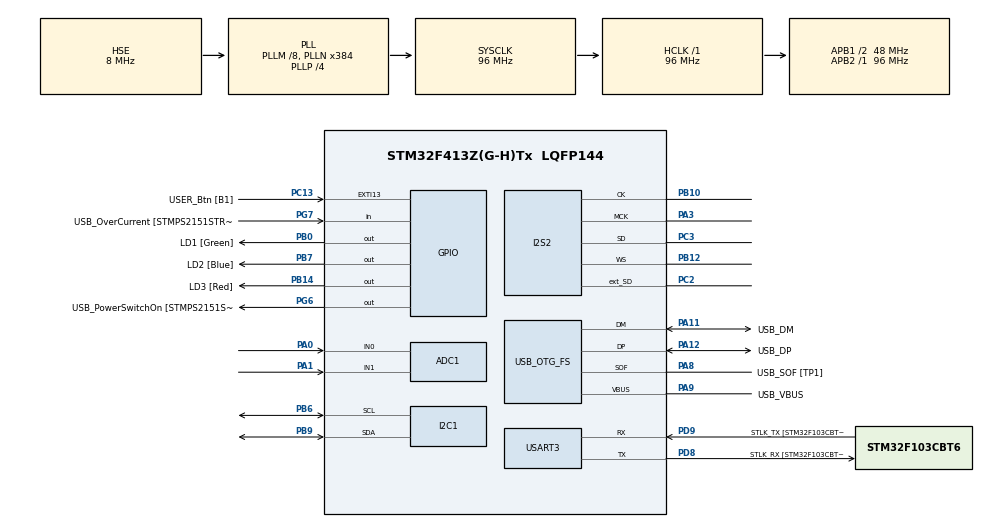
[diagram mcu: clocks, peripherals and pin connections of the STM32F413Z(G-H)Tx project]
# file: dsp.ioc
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ADC1.Channel-0\#ChannelRegularConversion=ADC_CHANNEL_0
ADC1.NbrOfConversionFlag=1
ADC1.Rank-0\#ChannelRegularConversion=1
ADC1.SamplingTime-0\#ChannelRegularConversion=ADC_SAMPLETIME_3CYCLES
ADC1.master=1
Dma.I2S2_EXT_RX.0.Direction=DMA_PERIPH_TO_MEMORY
Dma.I2S2_EXT_RX.0.FIFOMode=DMA_FIFOMODE_DISABLE
Dma.I2S2_EXT_RX.0.Instance=DMA1_Stream3
Dma.I2S2_EXT_RX.0.MemDataAlignment=DMA_MDATAALIGN_HALFWORD
Dma.I2S2_EXT_RX.0.MemInc=DMA_MINC_ENABLE
Dma.I2S2_EXT_RX.0.Mode=DMA_CIRCULAR
Dma.I2S2_EXT_RX.0.PeriphDataAlignment=DMA_PDATAALIGN_HALFWORD
Dma.I2S2_EXT_RX.0.PeriphInc=DMA_PINC_DISABLE
Dma.I2S2_EXT_RX.0.Priority=DMA_PRIORITY_LOW
Dma.Request0=I2S2_EXT_RX
Dma.Request1=SPI2_TX
Dma.SPI2_TX.1.Direction=DMA_MEMORY_TO_PERIPH
Dma.SPI2_TX.1.FIFOMode=DMA_FIFOMODE_DISABLE
Dma.SPI2_TX.1.Instance=DMA1_Stream4
Dma.SPI2_TX.1.MemDataAlignment=DMA_MDATAALIGN_HALFWORD
Dma.SPI2_TX.1.MemInc=DMA_MINC_ENABLE
Dma.SPI2_TX.1.Mode=DMA_CIRCULAR
Dma.SPI2_TX.1.PeriphDataAlignment=DMA_PDATAALIGN_HALFWORD
Dma.SPI2_TX.1.PeriphInc=DMA_PINC_DISABLE
Dma.SPI2_TX.1.Priority=DMA_PRIORITY_LOW
I2S2.AudioFreq=I2S_AUDIOFREQ_44K
I2S2.ErrorAudioFreq=-1.35 %
I2S2.FullDuplexMode=I2S_FULLDUPLEXMODE_ENABLE
I2S2.Instance=SPI$Index
I2S2.RealAudioFreq=43.402 KHz
I2S2.Standard=I2S_STANDARD_MSB
I2S2.VirtualMode=I2S_MODE_MASTER
Mcu.Family=STM32F4
Mcu.Name=STM32F413Z(G-H)Tx
Mcu.Package=LQFP144
NVIC.DMA1_Stream3_IRQn=true\:0\:0\:false\:false\:true\:false\:true
NVIC.DMA1_Stream4_IRQn=true\:0\:0\:false\:false\:true\:false\:true
NVIC.PriorityGroup=NVIC_PRIORITYGROUP_4
PA0.Signal=ADCx_IN0
PA1.Signal=ADCx_IN1
PA10.GPIO_Label=USB_ID
PA10.Signal=USB_OTG_FS_ID
PA11.GPIO_Label=USB_DM
PA11.Mode=Device_Only
PA11.Signal=USB_OTG_FS_DM
PA12.GPIO_Label=USB_DP
PA12.Mode=Device_Only
PA12.Signal=USB_OTG_FS_DP
PA13.GPIO_Label=TMS
PA13.Mode=Serial_Wire
PA13.Signal=SYS_JTMS-SWDIO
PA14.GPIO_Label=TCK
PA14.Mode=Serial_Wire
PA14.Signal=SYS_JTCK-SWCLK
PA3.Mode=Master_Clock_Activated
PA3.Signal=I2S2_MCK
PA8.GPIO_Label=USB_SOF [TP1]
PA8.Mode=Activate_SOF_FS
PA8.Signal=USB_OTG_FS_SOF
PA9.GPIO_Label=USB_VBUS
PA9.Mode=Activate_VBUS
PA9.Signal=USB_OTG_FS_VBUS
PB0.GPIO_Label=LD1 [Green]
PB0.Signal=GPIO_Output
PB10.Mode=Full_Duplex_Master
PB10.Signal=I2S2_CK
PB12.Mode=Full_Duplex_Master
PB12.Signal=I2S2_WS
PB14.GPIO_Label=LD3 [Red]
PB14.Signal=GPIO_Output
PB3.GPIO_Label=SWO
PB3.Signal=SYS_JTDO-SWO
PB6.Mode=I2C
PB6.Signal=I2C1_SCL
PB7.GPIO_Label=LD2 [Blue]
PB7.Signal=GPIO_Output
PB9.Mode=I2C
PB9.Signal=I2C1_SDA
PC13.GPIO_Label=USER_Btn [B1]
PC13.Signal=GPXTI13
PC14-OSC32_IN.Mode=LSE-External-Oscillator
PC14-OSC32_IN.Signal=RCC_OSC32_IN
PC15-OSC32_OUT.Mode=LSE-External-Oscillator
PC15-OSC32_OUT.Signal=RCC_OSC32_OUT
PC2.Mode=Full_Duplex_Master
PC2.Signal=I2S2_ext_SD
PC3.Mode=Full_Duplex_Master
PC3.Signal=I2S2_SD
PD8.GPIO_Label=STLK_RX [STM32F103CBT6_PA3]
PD8.Mode=Asynchronous
PD8.Signal=USART3_TX
PD9.GPIO_Label=STLK_TX [STM32F103CBT6_PA2]
PD9.Mode=Asynchronous
PD9.Signal=USART3_RX
PG6.GPIO_Label=USB_PowerSwitchOn [STMPS2151STR_EN]
PG6.Signal=GPIO_Output
PG7.GPIO_Label=USB_OverCurrent [STMPS2151STR_FAULT]
PG7.Signal=GPIO_Input
PH0\ -\ OSC_IN.GPIO_Label=MCO
PH0\ -\ OSC_IN.Mode=HSE-External-Clock-Source
PH0\ -\ OSC_IN.Signal=RCC_OSC_IN
PH1\ -\ OSC_OUT.Mode=HSE-External-Clock-Source
PH1\ -\ OSC_OUT.Signal=RCC_OSC_OUT
ProjectManager.HeapSize=0x200
ProjectManager.StackSize=0x400
ProjectManager.TargetToolchain=Makefile
RCC.48MHZClocksFreq_Value=24000000
RCC.AHBFreq_Value=96000000
RCC.APB1CLKDivider=RCC_HCLK_DIV2
RCC.APB1Freq_Value=48000000
RCC.APB1TimFreq_Value=96000000
RCC.APB2Freq_Value=96000000
RCC.APB2TimFreq_Value=96000000
RCC.CortexFreq_Value=96000000
RCC.HCLKFreq_Value=96000000
RCC.HSE_VALUE=8000000
RCC.HSI_VALUE=16000000
RCC.PLLI2SM=4
RCC.PLLI2SN=200
RCC.PLLM=8
RCC.PLLMUL=RCC_PLL_MUL9
RCC.PLLN=384
RCC.PLLP=RCC_PLLP_DIV4
RCC.PLLQ=8
RCC.PRESCALERUSB=RCC_USBCLKSOURCE_PLL_DIV1_5
RCC.SYSCLKFreq_VALUE=96000000
RCC.SYSCLKSource=RCC_SYSCLKSOURCE_PLLCLK
RCC.SYSCLKSourceVirtual=RCC_SYSCLKSOURCE_PLLCLK
RCC.USBFreq_Value=48000000
RCC.VCOOutputFreq_Value=384000000
SH.ADCx_IN0.0=ADC1_IN0,IN0
SH.ADCx_IN1.0=ADC1_IN1,IN1
USART3.VirtualMode=VM_ASYNC
USB_OTG_FS.VirtualMode=Device_Only
board=NUCLEO-F413ZH

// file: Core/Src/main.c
/* USER CODE BEGIN Header */
/**
  ******************************************************************************
  * @file           : main.c
  * @brief          : Main program body
  ******************************************************************************
  * @attention
  *
  * <h2><center>&copy; Copyright (c) 2021 STMicroelectronics.
  * All rights reserved.</center></h2>
  *
  * This software component is licensed by ST under BSD 3-Clause license,
  * the "License"; You may not use this file except in compliance with the
  * License. You may obtain a copy of the License at:
  *                        opensource.org/licenses/BSD-3-Clause
  *
  ******************************************************************************
  */
/* USER CODE END Header */
#include "main.h"

/* USER CODE BEGIN Includes */
#include "application.hpp"

////////////connection to codec//////////////
// pA3 ---> MCLK
// pB10 --> SCLK
// pB12 --> LRCLK
// pC2 ---> MISO (ADC)
// pC3 ---> MOSI (DAC)
//
// pB6 ---> SCL
// pB9 ---> SDA
/////////////////////////////////////////////

/* USER CODE END Includes */

ADC_HandleTypeDef hadc1;

I2C_HandleTypeDef hi2c1;

I2S_HandleTypeDef hi2s2;
DMA_HandleTypeDef hdma_i2s2_ext_rx;
DMA_HandleTypeDef hdma_spi2_tx;

UART_HandleTypeDef huart3;

PCD_HandleTypeDef hpcd_USB_OTG_FS;

void SystemClock_Config(void);
static void MX_GPIO_Init(void);
static void MX_DMA_Init(void);
static void MX_I2S2_Init(void);
static void MX_USART3_UART_Init(void);
static void MX_USB_OTG_FS_PCD_Init(void);
static void MX_ADC1_Init(void);
static void MX_I2C1_Init(void);

/* USER CODE BEGIN 0 */

int wait = 0;

/* USER CODE END 0 */

int main(void)
{

  /* MCU Configuration--------------------------------------------------------*/

  /* Reset of all peripherals, Initializes the Flash interface and the Systick. */
  HAL_Init();

  /* Configure the system clock */
  SystemClock_Config();

  /* Initialize all configured peripherals */
  MX_GPIO_Init();
  MX_DMA_Init();
  MX_I2S2_Init();
  MX_USART3_UART_Init();
  MX_USB_OTG_FS_PCD_Init();
  MX_ADC1_Init();
  MX_I2C1_Init();
  /* USER CODE BEGIN 2 */

  for(int i = 0; i < 1000000; i++);
  setup();
  for(int i = 0; i < 1000000; i++);
  HAL_I2SEx_TransmitReceive_DMA(&hi2s2, txBuf, rxBuf, 4);

  /* USER CODE END 2 */

  /* Infinite loop */
  while (1)
  {

  }
}

void HAL_I2SEx_TxRxHalfCpltCallback(I2S_HandleTypeDef *hi2s){
  do_process(&rxBuf[0],&rxBuf[1],&txBuf[0],&txBuf[1]);    //in,in,out,out
  //txBuf[0] = rxBuf[0];
  //txBuf[1] = rxBuf[1];
}

//this is not firing with default code!!!  see below.
//note:
//need to change I2SEx_TxRxDMACplt in stm32f4xx_hal_i2s_ex.c, so that it ends like:
//   }
//   HAL_I2SEx_TxRxCpltCallback(hi2s);
// }
//instead of:
//     }
//   }
// }
// https://community.st.com/s/question/0D50X0000AAJFwVSQX/bug-hali2sextxrxcpltcallback-never-fire-in-dma-circular-mode
void HAL_I2SEx_TxRxCpltCallback(I2S_HandleTypeDef *hi2s){
  //do_process(&rxBuf[2],&rxBuf[3],&txBuf[2],&txBuf[3]);
  txBuf[2] = 0;
  txBuf[3] = 0;
}

void SystemClock_Config(void)
{
  RCC_OscInitTypeDef RCC_OscInitStruct = {0};
  RCC_ClkInitTypeDef RCC_ClkInitStruct = {0};
  RCC_PeriphCLKInitTypeDef PeriphClkInitStruct = {0};

  /** Configure the main internal regulator output voltage
  */
  __HAL_RCC_PWR_CLK_ENABLE();
  __HAL_PWR_VOLTAGESCALING_CONFIG(PWR_REGULATOR_VOLTAGE_SCALE1);
  /** Initializes the RCC Oscillators according to the specified parameters
  * in the RCC_OscInitTypeDef structure.
  */
  RCC_OscInitStruct.OscillatorType = RCC_OSCILLATORTYPE_HSE;
  RCC_OscInitStruct.HSEState = RCC_HSE_BYPASS;
  RCC_OscInitStruct.PLL.PLLState = RCC_PLL_ON;
  RCC_OscInitStruct.PLL.PLLSource = RCC_PLLSOURCE_HSE;
  RCC_OscInitStruct.PLL.PLLM = 8;
  RCC_OscInitStruct.PLL.PLLN = 384;
  RCC_OscInitStruct.PLL.PLLP = RCC_PLLP_DIV4;
  RCC_OscInitStruct.PLL.PLLQ = 8;
  RCC_OscInitStruct.PLL.PLLR = 2;
  if (HAL_RCC_OscConfig(&RCC_OscInitStruct) != HAL_OK)
  {
    Error_Handler();
  }
  /** Initializes the CPU, AHB and APB buses clocks
  */
  RCC_ClkInitStruct.ClockType = RCC_CLOCKTYPE_HCLK|RCC_CLOCKTYPE_SYSCLK
                              |RCC_CLOCKTYPE_PCLK1|RCC_CLOCKTYPE_PCLK2;
  RCC_ClkInitStruct.SYSCLKSource = RCC_SYSCLKSOURCE_PLLCLK;
  RCC_ClkInitStruct.AHBCLKDivider = RCC_SYSCLK_DIV1;
  RCC_ClkInitStruct.APB1CLKDivider = RCC_HCLK_DIV2;
  RCC_ClkInitStruct.APB2CLKDivider = RCC_HCLK_DIV1;

  if (HAL_RCC_ClockConfig(&RCC_ClkInitStruct, FLASH_LATENCY_3) != HAL_OK)
  {
    Error_Handler();
  }
  PeriphClkInitStruct.PeriphClockSelection = RCC_PERIPHCLK_I2S_APB1|RCC_PERIPHCLK_CLK48;
  PeriphClkInitStruct.PLLI2S.PLLI2SN = 260;     //200
  PeriphClkInitStruct.PLLI2S.PLLI2SM = 4;
  PeriphClkInitStruct.PLLI2S.PLLI2SR = 2;
  PeriphClkInitStruct.PLLI2S.PLLI2SQ = 2;
  PeriphClkInitStruct.Clk48ClockSelection = RCC_CLK48CLKSOURCE_PLLQ;
  PeriphClkInitStruct.PLLI2SSelection = RCC_PLLI2SCLKSOURCE_PLLSRC;
  PeriphClkInitStruct.I2sApb1ClockSelection = RCC_I2SAPB1CLKSOURCE_PLLI2S;
  if (HAL_RCCEx_PeriphCLKConfig(&PeriphClkInitStruct) != HAL_OK)
  {
    Error_Handler();
  }
}

static void MX_ADC1_Init(void)
{

  ADC_ChannelConfTypeDef sConfig = {0};

  /** Configure the global features of the ADC (Clock, Resolution, Data Alignment and number of conversion)
  */
  hadc1.Instance = ADC1;
  hadc1.Init.ClockPrescaler = ADC_CLOCK_SYNC_PCLK_DIV4;
  hadc1.Init.Resolution = ADC_RESOLUTION_12B;
  hadc1.Init.ScanConvMode = DISABLE;
  hadc1.Init.ContinuousConvMode = DISABLE;
  hadc1.Init.DiscontinuousConvMode = DISABLE;
  hadc1.Init.ExternalTrigConvEdge = ADC_EXTERNALTRIGCONVEDGE_NONE;
  hadc1.Init.ExternalTrigConv = ADC_SOFTWARE_START;
  hadc1.Init.DataAlign = ADC_DATAALIGN_RIGHT;
  hadc1.Init.NbrOfConversion = 1;
  hadc1.Init.DMAContinuousRequests = DISABLE;
  hadc1.Init.EOCSelection = ADC_EOC_SINGLE_CONV;
  if (HAL_ADC_Init(&hadc1) != HAL_OK)
  {
    Error_Handler();
  }
  /** Configure for the selected ADC regular channel its corresponding rank in the sequencer and its sample time.
  */
  sConfig.Channel = ADC_CHANNEL_0;
  sConfig.Rank = 1;
  sConfig.SamplingTime = ADC_SAMPLETIME_3CYCLES;
  if (HAL_ADC_ConfigChannel(&hadc1, &sConfig) != HAL_OK)
  {
    Error_Handler();
  }

}

static void MX_I2C1_Init(void)
{

  hi2c1.Instance = I2C1;
  hi2c1.Init.ClockSpeed = 100000;
  hi2c1.Init.DutyCycle = I2C_DUTYCYCLE_2;
  hi2c1.Init.OwnAddress1 = 0;
  hi2c1.Init.AddressingMode = I2C_ADDRESSINGMODE_7BIT;
  hi2c1.Init.DualAddressMode = I2C_DUALADDRESS_DISABLE;
  hi2c1.Init.OwnAddress2 = 0;
  hi2c1.Init.GeneralCallMode = I2C_GENERALCALL_DISABLE;
  hi2c1.Init.NoStretchMode = I2C_NOSTRETCH_DISABLE;
  if (HAL_I2C_Init(&hi2c1) != HAL_OK)
  {
    Error_Handler();
  }

}

static void MX_I2S2_Init(void)
{

  hi2s2.Instance = SPI2;
  hi2s2.Init.Mode = I2S_MODE_MASTER_TX;
  hi2s2.Init.Standard = I2S_STANDARD_MSB;
  hi2s2.Init.DataFormat = I2S_DATAFORMAT_16B;
  hi2s2.Init.MCLKOutput = I2S_MCLKOUTPUT_ENABLE;
  hi2s2.Init.AudioFreq = I2S_AUDIOFREQ_48K;               //there's some oscillation with the setting of 44k here...
  hi2s2.Init.CPOL = I2S_CPOL_LOW;
  hi2s2.Init.ClockSource = I2S_CLOCK_PLL;
  hi2s2.Init.FullDuplexMode = I2S_FULLDUPLEXMODE_ENABLE;
  if (HAL_I2S_Init(&hi2s2) != HAL_OK)
  {
    Error_Handler();
  }

}

static void MX_USART3_UART_Init(void)
{

  huart3.Instance = USART3;
  huart3.Init.BaudRate = 115200;
  huart3.Init.WordLength = UART_WORDLENGTH_8B;
  huart3.Init.StopBits = UART_STOPBITS_1;
  huart3.Init.Parity = UART_PARITY_NONE;
  huart3.Init.Mode = UART_MODE_TX_RX;
  huart3.Init.HwFlowCtl = UART_HWCONTROL_NONE;
  huart3.Init.OverSampling = UART_OVERSAMPLING_16;
  if (HAL_UART_Init(&huart3) != HAL_OK)
  {
    Error_Handler();
  }

}

static void MX_USB_OTG_FS_PCD_Init(void)
{

  hpcd_USB_OTG_FS.Instance = USB_OTG_FS;
  hpcd_USB_OTG_FS.Init.dev_endpoints = 6;
  hpcd_USB_OTG_FS.Init.speed = PCD_SPEED_FULL;
  hpcd_USB_OTG_FS.Init.dma_enable = DISABLE;
  hpcd_USB_OTG_FS.Init.phy_itface = PCD_PHY_EMBEDDED;
  hpcd_USB_OTG_FS.Init.Sof_enable = ENABLE;
  hpcd_USB_OTG_FS.Init.low_power_enable = DISABLE;
  hpcd_USB_OTG_FS.Init.lpm_enable = DISABLE;
  hpcd_USB_OTG_FS.Init.battery_charging_enable = ENABLE;
  hpcd_USB_OTG_FS.Init.vbus_sensing_enable = ENABLE;
  hpcd_USB_OTG_FS.Init.use_dedicated_ep1 = DISABLE;
  if (HAL_PCD_Init(&hpcd_USB_OTG_FS) != HAL_OK)
  {
    Error_Handler();
  }

}

static void MX_DMA_Init(void)
{

  /* DMA controller clock enable */
  __HAL_RCC_DMA1_CLK_ENABLE();

  /* DMA interrupt init */
  /* DMA1_Stream3_IRQn interrupt configuration */
  HAL_NVIC_SetPriority(DMA1_Stream3_IRQn, 0, 0);
  HAL_NVIC_EnableIRQ(DMA1_Stream3_IRQn);
  /* DMA1_Stream4_IRQn interrupt configuration */
  HAL_NVIC_SetPriority(DMA1_Stream4_IRQn, 0, 0);
  HAL_NVIC_EnableIRQ(DMA1_Stream4_IRQn);

}

static void MX_GPIO_Init(void)
{
  GPIO_InitTypeDef GPIO_InitStruct = {0};

  /* GPIO Ports Clock Enable */
  __HAL_RCC_GPIOC_CLK_ENABLE();
  __HAL_RCC_GPIOH_CLK_ENABLE();
  __HAL_RCC_GPIOA_CLK_ENABLE();
  __HAL_RCC_GPIOB_CLK_ENABLE();
  __HAL_RCC_GPIOD_CLK_ENABLE();
  __HAL_RCC_GPIOG_CLK_ENABLE();

  /*Configure GPIO pin Output Level */
  HAL_GPIO_WritePin(GPIOB, LD1_Pin|LD3_Pin|LD2_Pin, GPIO_PIN_RESET);

  /*Configure GPIO pin Output Level */
  HAL_GPIO_WritePin(USB_PowerSwitchOn_GPIO_Port, USB_PowerSwitchOn_Pin, GPIO_PIN_RESET);

  /*Configure GPIO pin : USER_Btn_Pin */
  GPIO_InitStruct.Pin = USER_Btn_Pin;
  GPIO_InitStruct.Mode = GPIO_MODE_IT_RISING;
  GPIO_InitStruct.Pull = GPIO_NOPULL;
  HAL_GPIO_Init(USER_Btn_GPIO_Port, &GPIO_InitStruct);

  /*Configure GPIO pins : LD1_Pin LD3_Pin LD2_Pin */
  GPIO_InitStruct.Pin = LD1_Pin|LD3_Pin|LD2_Pin;
  GPIO_InitStruct.Mode = GPIO_MODE_OUTPUT_PP;
  GPIO_InitStruct.Pull = GPIO_NOPULL;
  GPIO_InitStruct.Speed = GPIO_SPEED_FREQ_LOW;
  HAL_GPIO_Init(GPIOB, &GPIO_InitStruct);

  /*Configure GPIO pin : USB_PowerSwitchOn_Pin */
  GPIO_InitStruct.Pin = USB_PowerSwitchOn_Pin;
  GPIO_InitStruct.Mode = GPIO_MODE_OUTPUT_PP;
  GPIO_InitStruct.Pull = GPIO_NOPULL;
  GPIO_InitStruct.Speed = GPIO_SPEED_FREQ_LOW;
  HAL_GPIO_Init(USB_PowerSwitchOn_GPIO_Port, &GPIO_InitStruct);

  /*Configure GPIO pin : USB_OverCurrent_Pin */
  GPIO_InitStruct.Pin = USB_OverCurrent_Pin;
  GPIO_InitStruct.Mode = GPIO_MODE_INPUT;
  GPIO_InitStruct.Pull = GPIO_NOPULL;
  HAL_GPIO_Init(USB_OverCurrent_GPIO_Port, &GPIO_InitStruct);

}

void Error_Handler(void)
{
  __disable_irq();
  while (1)
  {
  }
}

/************************ (C) COPYRIGHT STMicroelectronics *****END OF FILE****/
